# STM32H503 register map
File version: 1.5
CPU: CM33 r0p0, little endian, MPU, FPU, 4 interrupt priority bits
Registers are 32-bit, read-write, reset 0x0 unless marked. A register's access mark holds for its fields unless they carry their own. Offsets are from the block's base; [hi:lo] are bit positions; {n}, {i} and the like mark numbered series; 'fields as' and 'values as' point back to an identical list.

## SBS — System configuration, boot and security
Base 0x44000400
0x10 HDPLCR reset 0xB4 — SBS temporal isolation control register
  [7:0] INCR_HDPL — increment HDPL value Other: all other values allow a HDPL level increment.
    106=Increment HDPL value
0x14 HDPLSR ro reset not defined — SBS temporal isolation status register
  [7:0] HDPL — temporal isolation level This bitfield returns the current temporal isolation level.
    81=Protection level to be used to execute and protect immutable Root of Trust (IROT) stage; 111=Protection level to be used to execute the application; 138=Protection level to be used to execute and protect an updatable Root of Trust (UROT) stage; 180=Protection level reserved for ST code and data
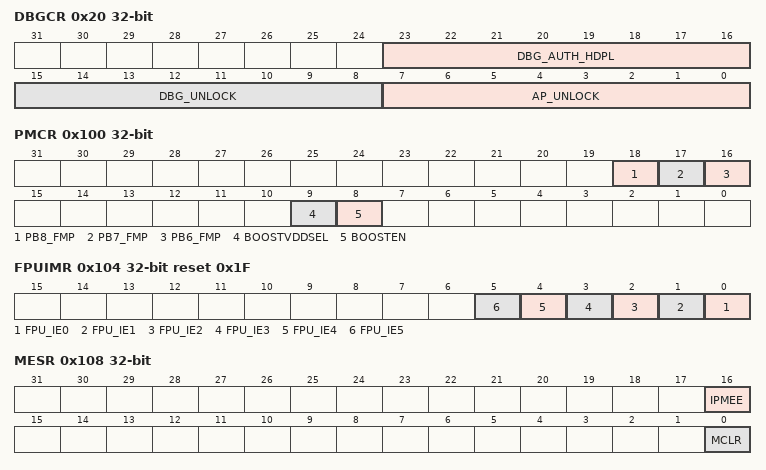
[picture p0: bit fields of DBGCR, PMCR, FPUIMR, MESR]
0x20 DBGCR — SBS debug control register
  [23:16] DBG_AUTH_HDPL — authenticated debug temporal isolation level Writing to this bitfield defines at which HDPL the authenticated debug opens. Note: Writing any other values is ignored. Reading any other value means the debug never opens.
    81=HDPL1 (Protection level to be used to execute and protect immutable Root of Trust (IROT) stage); 111=HDPL3 (Protection level to be used to execute the application); 138=HDPL2 (Protection level to be used to execute and protect an updatable Root of Trust (UROT) stage)
  [15:8] DBG_UNLOCK — debug unlock when DBG_AUTH_HDPL is reached Write 0xB4 to this bitfield to open the debug when HDPL in SBS_HDPLSR equals to DBG_AUTH_HDPL in this register.
    180=Unlocked (Debug unlocked when HDPLSR:HDPL is equal to DBG_AUTH_HDPL)
  [7:0] AP_UNLOCK — access port unlock Write 0xB4 to this bitfield to open the device access port.
    180=Unlocked (Device access port unlocked)
0x24 DBGLOCKR reset 0xB4 — SBS debug lock register
  [7:0] DBGCFG_LOCK — debug configuration lock Reading this bitfield returns 0x6A if the bitfield value is different from 0xB4. 0xC3 is the recommended value to lock the debug configuration using this bitfield. Other: Writes to SBS_DBGCR ignored
    on read: 106=Locked (Debug configuration register (DBGCR) locked); 180=Unlocked (Debug configuration register (DBGCR) unlocked) | on write: 180=Unlocked (Debug configuration register (DBGCR) unlocked); 195=Locked (Debug configuration register (DBGCR) locked)
0x100 PMCR — SBS product mode and configuration register
  [18] PB8_FMP — Fast-mode Plus command on PB(8)
    0=Disabled (Fast-mode Plus mode on PB8 disabled); 1=Enabled (Fast-mode Plus mode on PB8 enabled)
  [17] PB7_FMP — Fast-mode Plus command on PB(7)
    0=Disabled (Fast-mode Plus mode on PB7 disabled); 1=Enabled (Fast-mode Plus mode on PB7 enabled)
  [16] PB6_FMP — Fast-mode Plus command on PB(6)
    0=Disabled (Fast-mode Plus mode on PB6 disabled); 1=Enabled (Fast-mode Plus mode on PB6 enabled)
  [9] BOOSTVDDSEL — booster V DD selection Note: Booster must not be used when V DDA 2.7 V, but V DD 2.7 V (add current consumption). Note: When both V DD 2.7 V and V DDA 2.7 V, booster is needed to get full AC performances from I/O analog switches.
  [8] BOOSTEN — booster enable Set this bit to reduce the total harmonic distortion of the analog switch when the processor supply is below 2.7 V. The booster can be activated to guaranty AC performance on analog switch when the supply is below 2.7 V. When the booster is activated, the analog switch performances are the same as with the full voltage range.
0x104 FPUIMR access not given reset 0x1F — SBS FPU interrupt mask register
  [all] fields
    0=Disabled (Interrupt disabled); 1=Enabled (Interrupt enabled)
  [n] FPU_IE{n} (n=0..5) — FPU interrupt enable
0x108 MESR — SBS memory erase status register
  [16] IPMEE write-1-clears — end-of-erase status for ICACHE This bit shows the status of the protection for ICACHE. It is set by hardware and reset by software.
    on read: 0=EraseInProgress (ICACHE erase ongoing); 1=EraseCompleted (ICACHE erase completed) | on write: 1=Clear ICACHE erase status flag
  [0] MCLR write-1-clears — erase after reset status This bit shows the status of the protection for SRAM2, BKPRAM, ICACHE, ICACHE. It is set by hardware and reset by software
    on read: 0=EraseInProgress (Memory erase in progress); 1=EraseComplete (Memory erase complete) | on write: 1=Clear memory erase status flag
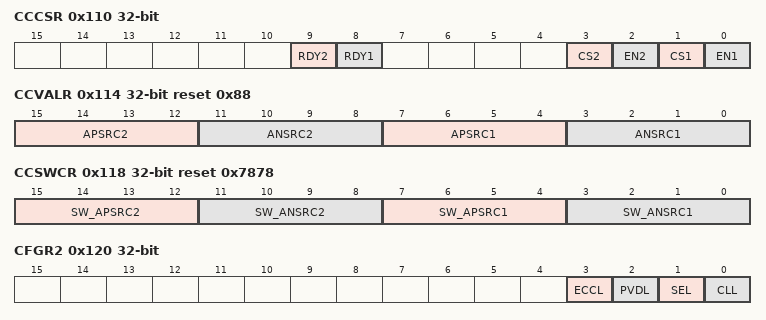
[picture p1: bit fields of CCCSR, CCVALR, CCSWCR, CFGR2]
0x110 CCCSR access per field — SBS compensation cell for I/Os control and status register
  [9] RDY2 ro — VDDIO2 compensation cell ready flag This bit provides the status of the VDDIO2 compensation cell.
    0=NotReady (VDDIO compensation cell not ready); 1=Ready (VDDIO compensation cell ready)
  [8] RDY1 ro — VDDIO compensation cell ready flag This bit provides the status of the compensation cell.
    values as RDY2
  [3] CS2 rw — code selection for VDDIO2 power rail (reset value set to 1) This bit selects the code to be applied for the I/O compensation cell.
    0=Cell (Code from cell selected); 1=CCSWCR (Code from CCSWCR selected)
  [2] EN2 rw — enable compensation cell for VDDIO2 power rail This bit enables the I/O compensation cell.
    0=Disabled (I/O compensation cell disabled); 1=Enabled (I/O compensation cell enabled)
  [1] CS1 rw — code selection for VDDIO power rail (reset value set to 1) This bit selects the code to be applied for the I/O compensation cell.
    values as CS2
  [0] EN1 rw — enable compensation cell for VDDIO power rail This bit enables the I/O compensation cell.
    values as EN2
0x114 CCVALR ro reset 0x88 — SBS compensation cell for I/Os value register
  [15:12] APSRC2 — compensation value for the PMOS transistor This value is provided by the cell and must be interpreted by the processor to compensate the slew rate in the functional range.
  [11:8] ANSRC2 — Compensation value for the NMOS transistor This value is provided by the cell and must be interpreted by the processor to compensate the slew rate in the functional range.
  [7:4] APSRC1 — compensation value for the PMOS transistor This value is provided by the cell and must be interpreted by the processor to compensate the slew rate in the functional range.
  [3:0] ANSRC1 — compensation value for the NMOS transistor This value is provided by the cell and must be interpreted by the processor to compensate the slew rate in the functional range.
0x118 CCSWCR reset 0x7878 — SBS compensation cell for I/Os software code register
  [15:12] SW_APSRC2 — PMOS compensation code for the V DDIO power rails This bitfield is written by software to define an I/O compensation cell code for PMOS transistors of the VDDIO power rail. This code is applied to the I/O when CS2 is set in SBS_CCSR.
  [11:8] SW_ANSRC2 — NMOS compensation code for VDDIO power rails This bitfield is written by software to define an I/O compensation cell code for NMOS transistors of the VDD power rail. This code is applied to the I/O when CS2 is set in SBS_CCSR.
  [7:4] SW_APSRC1 — PMOS compensation code for the VDD power rails This bitfield is written by software to define an I/O compensation cell code for PMOS transistors of the VDDIO power rail. This code is applied to the I/O when CS1 is set in SBS_CCSR.
  [3:0] SW_ANSRC1 — NMOS compensation code for VDD power rails This bitfield is written by software to define an I/O compensation cell code for NMOS transistors of the VDD power rail. This code is applied to the I/O when CS1 is set in SBS_CCSR.
0x120 CFGR2 — SBS Class B register
  [all] fields
    0=Disconnected (Flag/Interrupt disconnected from timer break inputs); 1=Connected (Flag/Interrupt connected to timer break inputs)
  [3] ECCL — ECC lock This bit is set and cleared by software. It can be used to enable and lock the Flash memory double ECC error with break input of TIM1.
  [2] PVDL — PVD lock This bit is set by software and cleared only by a system reset. It can be used to enable and lock the PVD connection with TIM1 break inputs.
  [1] SEL — SRAM ECC error lock This bit is set by software and cleared only by a system reset. It can be used to enable and lock the SRAM double ECC error signal with break input of TIM1.
  [0] CLL — core lockup lock This bit is set by software and cleared only by a system reset. It can be used to enable and lock the lockup (HardFault) output of Cortex-M33 with TIM1 break inputs.
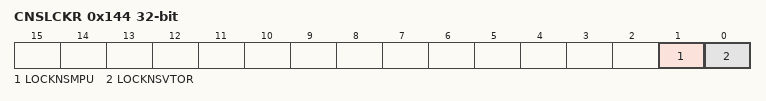
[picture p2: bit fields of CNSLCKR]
0x144 CNSLCKR — SBS CPU lock register
  [1] LOCKNSMPU — MPU register lock This bit is set by software and cleared only by a system reset. When set, this bit disables write access to MPU_CTRL_NS, MPU_RNR_NS and MPU_RBAR_NS registers.
    0=Unlocked (MPU registers write enabled); 1=Locked (MPU registers write disabled)
  [0] LOCKNSVTOR — VTOR_NS register lock This bit is set by software and cleared only by a system reset.
    0=Unlocked (VTOR_NS register write enabled); 1=Locked (VTOR_NS register write disabled)
0x14C ECCNMIR — SBS flift ECC NMI mask register
  [0] ECCNMI_MASK_EN — NMI behavior setup when a double ECC error occurs on flitf data part
    0=Enabled (NMI enabled); 1=Disabled (NMI disabled)
